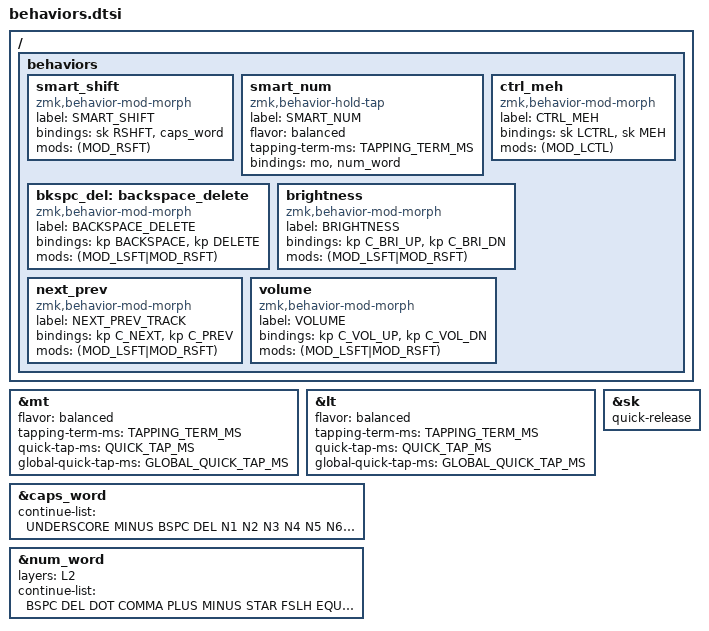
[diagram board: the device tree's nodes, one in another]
#define TAPPING_TERM_MS 280
#define QUICK_TAP_MS 175
#define GLOBAL_QUICK_TAP_MS 150

// cancel caps-word, num-word and smart-mouse
#define CANCEL &kp K_CANCEL

&mt {
  flavor = "balanced";
  tapping-term-ms = <TAPPING_TERM_MS>;
  quick-tap-ms = <QUICK_TAP_MS>;
  global-quick-tap-ms = <GLOBAL_QUICK_TAP_MS>;
};

&lt {
  flavor = "balanced";
  tapping-term-ms = <TAPPING_TERM_MS>;
  quick-tap-ms = <QUICK_TAP_MS>;
  global-quick-tap-ms = <GLOBAL_QUICK_TAP_MS>;
};

&sk {
  quick-release;
};

// mods deactivate caps-word, requires PR https://github.com/zmkfirmware/zmk/pull/1451
&caps_word {
  continue-list = <UNDERSCORE MINUS BSPC DEL N1 N2 N3 N4 N5 N6 N7 N8 N9 N0>;
  // /delete-property/ ignore-modifiers;
};

// From: https://github.com/urob/zmk-config/
// num-word, requires PR https://github.com/zmkfirmware/zmk/pull/1451
// Adds arrows and shift to smart layer for more comfortable navigation/selection moves
&num_word {
  layers = <L2>;
  continue-list = <BSPC DEL DOT COMMA PLUS MINUS STAR FSLH EQUAL RSHFT LEFT RIGHT UP DOWN>;
};

/ {
  behaviors {
    /*
     - tap: sticky shift
     - double-tap: caps-word (shift + tap mod-morph)
     - hold: shift

     From: https://github.com/urob/zmk-config/
     */
    /omit-if-no-ref/ smart_shift: smart_shift {
      label = "SMART_SHIFT";
      compatible = "zmk,behavior-mod-morph";
      bindings = <&sk RSHFT>, <&caps_word>;
      mods = <(MOD_RSFT)>;
      #binding-cells = <0>;
    };


    /*
     - tap: num-word
     - hold: &mo layer

     From: https://github.com/urob/zmk-config/
     */
    /omit-if-no-ref/ smart_num: smart_num {
      label = "SMART_NUM";
      compatible = "zmk,behavior-hold-tap";
      flavor = "balanced";
      tapping-term-ms = <TAPPING_TERM_MS>;
      bindings = <&mo>, <&num_word>;
      #binding-cells = <2>;
    };


    /*
     - tap: sticky ctrl
     - hold: ctrl
     - double-tap: sticky meh (ctrl + tap mod-morph)
     - tap + hold: meh (ctrl + hold mod-morph)

     From: https://github.com/urob/zmk-config/
     */
    /omit-if-no-ref/ ctrl_meh: ctrl_meh {
      label = "CTRL_MEH";
      compatible = "zmk,behavior-mod-morph";
      bindings = <&sk LCTRL>, <&sk MEH>;
      mods = <(MOD_LCTL)>;
      #binding-cells = <0>;
    };

    /*
     - tap: backspace
     - hold: repeat backspace
     - shift + tap: delete
     - shift + hold: repeat delete

     From: https://zmk.dev/docs/behaviors/mod-morph#advanced-configuration
     */
    /omit-if-no-ref/ bkspc_del: backspace_delete {
      label = "BACKSPACE_DELETE";
      compatible = "zmk,behavior-mod-morph";
      bindings = <&kp BACKSPACE>, <&kp DELETE>;
      mods = <(MOD_LSFT|MOD_RSFT)>;
      #binding-cells = <0>;
    };

    /*
     - tap: brightness up
     - hold: repeat brightness up
     - shift + tap: brightness down
     - shift + hold: repeat brightness down
     */
    /omit-if-no-ref/ brightness: brightness {
      label = "BRIGHTNESS";
      compatible = "zmk,behavior-mod-morph";
      bindings = <&kp C_BRI_UP>, <&kp C_BRI_DN>;
      mods = <(MOD_LSFT|MOD_RSFT)>;
      #binding-cells = <0>;
    };

    /*
     - tap: next track
     - shift + tap: prev track
     */
    /omit-if-no-ref/ next_prev: next_prev {
      label = "NEXT_PREV_TRACK";
      compatible = "zmk,behavior-mod-morph";
      bindings = <&kp C_NEXT>, <&kp C_PREV>;
      mods = <(MOD_LSFT|MOD_RSFT)>;
      #binding-cells = <0>;
    };

    /*
     - tap: next track
     - shift + tap: prev track
     */
    /omit-if-no-ref/ volume: volume {
      label = "VOLUME";
      compatible = "zmk,behavior-mod-morph";
      bindings = <&kp C_VOL_UP>, <&kp C_VOL_DN>;
      mods = <(MOD_LSFT|MOD_RSFT)>;
      #binding-cells = <0>;
    };
  };
};
